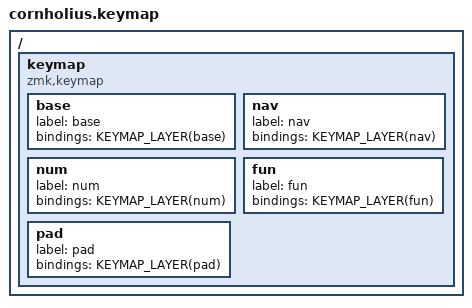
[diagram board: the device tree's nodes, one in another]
/*
 * Cornholius (ebastler) — thin keymap. Wireless nRF52840 unibody "drop-in" PCB for
 * the Foostan Cornelius; the board itself is vendored (HWv2-migrated) under
 * boards/shields/cornholius/. Superset (4x12 = 48 keys): the outer pinky column,
 * the fourth-row outer modifier keys and the two outer thumbs map to reserved master
 * slots (currently inactive) — the board runs the canonical 34-key core. All content
 * lives in config/shared/.
 */

#include <behaviors.dtsi>
#include <dt-bindings/zmk/keys.h>
#include <dt-bindings/zmk/bt.h>
#include <dt-bindings/zmk/outputs.h>

#include "geometry/geom_cornholius.h"

#include "shared/keys_de.h"
#include "shared/settings.dtsi"
#include "shared/behaviors.dtsi"
#include "shared/macros.dtsi"
#include "shared/combos.dtsi"
#include "shared/core_blocks.dtsi"

/ {
    keymap {
        compatible = "zmk,keymap";

        base { label = "base"; bindings = <KEYMAP_LAYER(base)>; };
        nav  { label = "nav";  bindings = <KEYMAP_LAYER(nav)>;  };
        num  { label = "num";  bindings = <KEYMAP_LAYER(num)>;  };
        fun  { label = "fun";  bindings = <KEYMAP_LAYER(fun)>;  };
        pad  { label = "pad";  bindings = <KEYMAP_LAYER(pad)>;  };
    };
};
